# CC2756 register map
File version: 1.0
CPU: CM4 r0p4, little endian, no MPU, no FPU, VTOR, 3 interrupt priority bits
Registers are 32-bit, read-write, reset 0x0 unless marked. A register's access mark holds for its fields unless they carry their own. Offsets are from the block's base; [hi:lo] are bit positions; lines under a group give offsets from that group.

## EVTULL — This is top module of Event Fabric for LOKI
Base 0x40005000
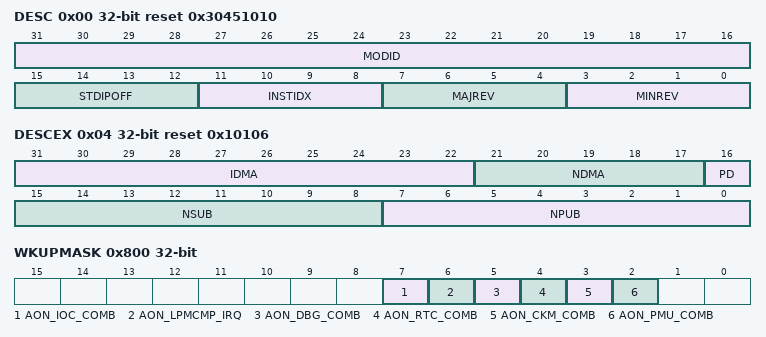
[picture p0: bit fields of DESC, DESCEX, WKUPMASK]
0x00 DESC ro reset 0x30451010 — Description Register.This register provides IP module ID, revision information, instance index and standard MMR registers offset.
  [31:16] MODID — Module identifier used to uniquely identify this IP.
  [15:12] STDIPOFF — Standard IP MMR block offset. Standard IP MMRs are the set of from aggregated IRQ registers till DTB. 0: Standard IP MMRs do not exist 0x1-0xF: Standard IP MMRs begin at offset of (64*STDIPOFF from the base IP address)
  [11:8] INSTIDX — IP Instance ID number. If multiple instances of IP exist in the device, this field can identify the instance number (0-15).
  [7:4] MAJREV — Major revision of IP (0-15).
  [3:0] MINREV — Minor revision of IP (0-15).
0x04 DESCEX ro reset 0x10106 — Extended Description Register. This register provides configuration details of the IP to software drivers and end users.
  [31:22] IDMA — Number of DMA input channels
  [21:17] NDMA — Number of DMA output channels
  [16] PD — Power Domain. 0 : SVT 1 : ULL
  [15:8] NSUB — Number of Subscribers
  [7:0] NPUB — Number of Publishers
0x64 DTB — Digital test bus control register. This register can be used to bring out IP internal signals to the pads for observation. 16 signals can be observed per select value.
  [0] SEL — Digital test bus selection mux control. Non-zero select values output a 16 bit selected group of signals per value.
0x404 RTCCPTSEL — Output Selection for RTCCPT Register.
  [6:0] PUBID — Read/write selection value. Writing any other value than values defined by a ENUM may result in undefined behavior.
    7=AON_IOC_COMB (IOC synchronous combined event, controlled by IOC:EVTCFG); 6=AON_LPMCMP_IRQ (AON LPCMP interrupt, controlled by SYS0:LPCMPCFG); 5=AON_DBG_COMB (DebugSS combined interrupt, interrupt flags can be found here DBGSS:MIS); 4=AON_RTC_COMB (AON_RTC event, controlled by the RTC:IMASK setting); 3=AON_CKM_COMB (CKMD combined interrupt request, interrupt flags can be found here CKMD:MIS); 2=AON_PMU_COMB (PMU combined interrupt request for BATMON, interrupt flags can be found here PMUD:EVENT); 0=NONE (Always inactive)
0x800 WKUPMASK — WAKEUP Mask Register.
  [all] fields
    1=EN (Wakeup enabled); 0=DIS (Wakeup disabled)
  [7] AON_IOC_COMB — Wake-up mask for AON_IOC_COMB.
  [6] AON_LPMCMP_IRQ — Wake-up mask for AON_LPCMP_IRQ.
  [5] AON_DBG_COMB — Wake-up mask for AON_DBG_COMB.
  [4] AON_RTC_COMB — Wake-up mask for AON_RTC_COMB.
  [3] AON_CKM_COMB — Wake-up mask for AON_CKM_COMB.
  [2] AON_PMU_COMB — Wake-up mask for AON_PMU_COMB.

## HSM — HSM is a Root of Trust Engine that protects valuable assets, such as secret keys for embedded security sensitive applications in a Trusted Execution Environment
Base 0x40053000
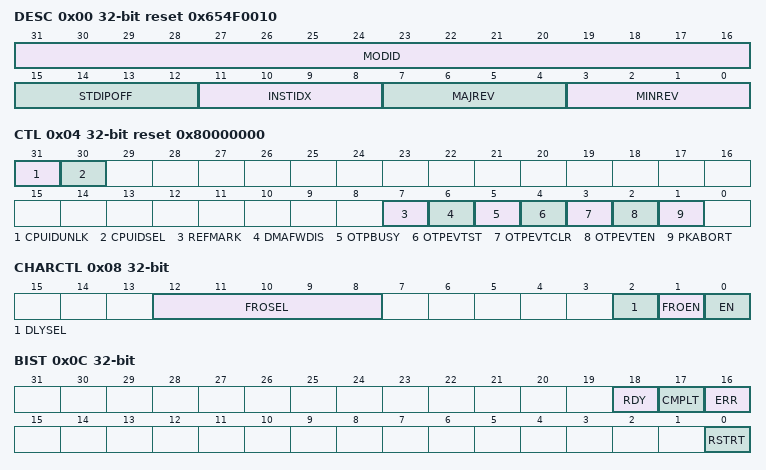
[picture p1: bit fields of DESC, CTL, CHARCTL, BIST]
0x00 DESC ro reset 0x654F0010 — Description Register. This register provides IP module ID, revision information, instance index and standard MMR registers offset.
  [31:16] MODID — Module identification contains a unique peripheral identification number.
  [15:12] STDIPOFF — Standard IP MMR block offset. Standard IP MMRs are the set of from aggregated IRQ registers till DTB. 0: Standard IP MMRs do not exist 0x1-0xF: Standard IP MMRs begin at offset of (64*STDIPOFF from the base IP address)
  [11:8] INSTIDX — IP Instance ID number. If multiple instances of IP exist in the device, this field can identify the instance number (0-15).
  [7:4] MAJREV — Major revision of IP
  [3:0] MINREV — Minor revision of IP
0x04 CTL reset 0x80000000 — Control Register
  [31] CPUIDUNLK — CPUID Lock. Sets sticky '0' lock for CTL.CPUIDSEL
    1=UNLOCK; 0=LOCK
  [30] CPUIDSEL — CPUID Select. Selects between ROMFW CPUID and Application CPUID
    1=ROMID (Assert); 0=APPID (Dassert)
  [7] REFMARK — Refresher Marker. Trigger writting refresh marker. This bit is auto cleared when programming is done
    1=TRG (Trigger/Busy); 0=DONE
  [6] DMAFWDIS — DMA Firewall Disable
    1=DIS (DMA Firewall Disabled); 0=EN (DMA Firewall Enabled)
  [5] OTPBUSY ro — OTP Busy. OTP contoller is busy
  [4] OTPEVTST ro — OTP Event Status.
    1=START (OTP Start); 0=DONE (OTP Done)
  [3] OTPEVTCLR wo — OTP Event Clear
    1=CLR (Request PKA Abort)
  [2] OTPEVTEN — OTP Event Enable
    1=EN (OTP Event Enable); 0=DIS (OTP Event Disable)
  [1] PKABORT wo — PKA Abort. Writing 1 to this bit requests PKA Abort, writing 0 has no effect
    1=REQ (Request PKA Abort)
0x08 CHARCTL — Characterization Controls for FRO
  [12:8] FROSEL — Selects FRO to characterize
  [2] DLYSEL — Selects delay in target FRO.This input must only be changed when CHARCTL.FROEN = 0
    1=TAP95 (Selects a tap on the approx. 95% of full length); 0=FULL (Selects the full chain length)
  [1] FROEN — Enables selected FRO
    1=EN (Enabled); 0=DIS (Disabled)
  [0] EN — Enables` characterization
    1=EN (Enabled); 0=DIS (Disabled)
0x0C BIST — BIST Controls and Status for CRNG
  [18] RDY ro — CRNG BIST ready. When 1, BIST and health checks are complete
  [17] CMPLT ro — CRNG BIST Complete. When 1, BIST checks are done
  [16] ERR ro — CRNG BIST Error. When 1, BIST failed
  [0] RSTRT — CRNG BIST Restart. When 1, starts BIST sequence. Ignored when BIST.RDY = 0
